# STM32U545 register map
File version: 1.7
CPU: CM33 r0p1, little endian, MPU, FPU, 4 interrupt priority bits
Registers are 32-bit, read-write, reset 0x0 unless marked. A register's access mark holds for its fields unless they carry their own. Offsets are from the block's base; [hi:lo] are bit positions; {n}, {i} and the like mark numbered series; 'fields as' and 'values as' point back to an identical list.

## USB — USB full speed
Base 0x40016000
Same registers: SEC_USB 0x50016000
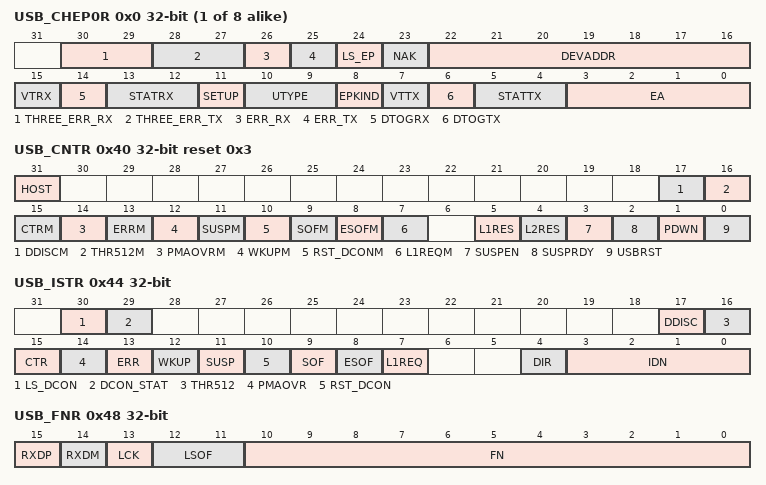
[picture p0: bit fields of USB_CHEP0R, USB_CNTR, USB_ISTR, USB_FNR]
{0x0+4i} USB_CHEP{i}R access per field (i=0..7) — USB endpoint/channel {i} register
  [30:29] THREE_ERR_RX rw — Three errors for an IN transaction
    0=Less than 3 errors received; 1=More than 3 errors received, last error is timeout error; 2=More than 3 errors received, last error is data error (CRC error); 3=More than 3 errors received, last error is protocol error (invalid PID, false EOP, bitstuffing error, SYNC error)
  [28:27] THREE_ERR_TX rw — Three errors for an OUT or SETUP transaction
    values as THREE_ERR_RX
  [26] ERR_RX rw — Received error for an IN transaction
  [25] ERR_TX rw — Received error for an OUT/SETUP transaction
  [24] LS_EP rw — Low speed endpoint host with HUB only
    0=Full speed endpoint; 1=Low speed endpoint
  [23] NAK rw — Host mode
  [22:16] DEVADDR rw — Host mode
  [15] VTRX rw — USB valid transaction received
  [14] DTOGRX wo — Data Toggle, for reception transfers
  [13:12] STATRX wo — Status bits, for reception transfers
  [11] SETUP ro — Setup transaction completed
  [10:9] UTYPE rw — USB type of transaction
  [8] EPKIND rw — endpoint/channel kind
  [7] VTTX rw — Valid USB transaction transmitted
  [6] DTOGTX wo — Data toggle, for transmission transfers
  [5:4] STATTX wo — Status bits, for transmission transfers
  [3:0] EA rw — endpoint/channel address
0x40 USB_CNTR access per field reset 0x3
  [31] HOST rw — HOST mode
    0=USB Device function; 1=USB host function
  [17] DDISCM rw — Device disconnection mask
    0=Device disconnection interrupt disabled; 1=Device disconnection interrupt enabled
  [16] THR512M rw — 512 byte threshold interrupt mask
    0=512 byte threshold interrupt disabled; 1=512 byte threshold interrupt enabled
  [15] CTRM rw — Correct transfer interrupt mask
    0=Correct transfer (CTR) interrupt disabled; 1=CTR interrupt enabled, an interrupt request is generated when the corresponding bit in the USB_ISTR register is set
  [14] PMAOVRM rw — Packet memory area over / underrun interrupt mask
    0=PMAOVR interrupt disabled; 1=PMAOVR interrupt enabled, an interrupt request is generated when the corresponding bit in the USB_ISTR register is set
  [13] ERRM rw — Error interrupt mask
    0=ERR interrupt disabled; 1=ERR interrupt enabled, an interrupt request is generated when the corresponding bit in the USB_ISTR register is set
  [12] WKUPM rw — Wakeup interrupt mask
    0=WKUP interrupt disabled; 1=WKUP interrupt enabled, an interrupt request is generated when the corresponding bit in the USB_ISTR register is set
  [11] SUSPM rw — Suspend mode interrupt mask
    0=Suspend mode request (SUSP) interrupt disabled; 1=SUSP interrupt enabled, an interrupt request is generated when the corresponding bit in the USB_ISTR register is set
  [10] RST_DCONM rw — USB reset request (Device mode) or device connect/disconnect (Host mode) interrupt mask
    0=RESET interrupt disabled; 1=RESET interrupt enabled, an interrupt request is generated when the corresponding bit in the USB_ISTR register is set
  [9] SOFM rw — Start of frame interrupt mask
    0=SOF interrupt disabled; 1=SOF interrupt enabled, an interrupt request is generated when the corresponding bit in the USB_ISTR register is set
  [8] ESOFM rw — Expected start of frame interrupt mask
    0=Expected start of frame (ESOF) interrupt disabled; 1=ESOF interrupt enabled, an interrupt request is generated when the corresponding bit in the USB_ISTR register is set
  [7] L1REQM rw — LPM L1 state request interrupt mask
    0=LPM L1 state request (L1REQ) interrupt disabled; 1=L1REQ interrupt enabled, an interrupt request is generated when the corresponding bit in the USB_ISTR register is set
  [5] L1RES rw — L1 remote wakeup / resume driver
    0=No effect; 1=Send 50 us remote-wakeup signaling to host
  [4] L2RES rw — L2 remote wakeup / resume driver
    0=No effect; 1=Send L2 resume signaling to device
  [3] SUSPEN rw — Suspend state enable
    0=B_0x0_DEVICE_MODE (No effect.); 1=B_0x1_DEVICE_MODE (Enter L1/L2 suspend)
  [2] SUSPRDY ro — Suspend state effective
    0=Normal operation; 1=Suspend state
  [1] PDWN rw — Power down
    0=Exit power down; 1=Enter power down mode
  [0] USBRST rw — USB Reset
    0=B_0x0_DEVICE_MODE (No effect); 1=B_0x1_DEVICE_MODE (USB core is under reset)
0x44 USB_ISTR access per field — USB interrupt status register
  [30] LS_DCON ro — Low speed device connected
  [29] DCON_STAT ro — Device connection status
    0=No device connected; 1=FS or LS device connected to the host
  [17] DDISC rw — Device connection
  [16] THR512 rw — 512 byte threshold interrupt
  [15] CTR ro — Completed transfer in host mode
  [14] PMAOVR rw — Packet memory area over / underrun
  [13] ERR rw — Error
  [12] WKUP rw — Wakeup
  [11] SUSP rw — Suspend mode request
  [10] RST_DCON rw — USB reset request (Device mode) or device connect/disconnect (Host mode)
  [9] SOF rw — Start of frame
  [8] ESOF rw — Expected start of frame
  [7] L1REQ rw — LPM L1 state request
  [4] DIR ro — Direction of transaction
  [3:0] IDN ro — Device Endpoint / host channel identification number
0x48 USB_FNR ro (reset mask 0xFFFFF000) — USB frame number register
  [15] RXDP — Receive data + line status
  [14] RXDM — Receive dataline status
  [13] LCK — Locked
  [12:11] LSOF — Lost SOF
  [10:0] FN — Frame number
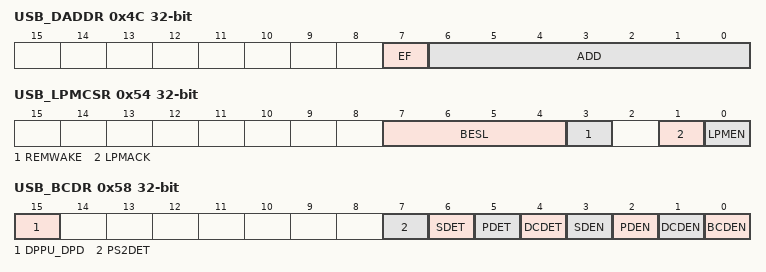
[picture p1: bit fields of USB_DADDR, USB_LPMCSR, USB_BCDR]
0x4C USB_DADDR
  [7] EF — Enable function
  [6:0] ADD — Device address
0x54 USB_LPMCSR access per field
  [7:4] BESL ro — BESL value
  [3] REMWAKE ro — bRemoteWake value
  [1] LPMACK rw — LPM token acknowledge enable
    0=the valid LPM token is NYET; 1=the valid LPM token is ACK
  [0] LPMEN rw — LPM support enable
0x58 USB_BCDR access per field
  [15] DPPU_DPD rw — DP pull-up / DPDM pull-down
  [7] PS2DET ro — DM pull-up detection status
    0=Normal port detected (connected to SDP, ACA, CDP or DCP); 1=PS2 port or proprietary charger detected
  [6] SDET ro — Secondary detection (SD) status
    0=CDP detected; 1=DCP detected
  [5] PDET ro — Primary detection (PD) status
    0=no BCD support detected (connected to SDP or proprietary device); 1=BCD support detected (connected to ACA, CDP or DCP)
  [4] DCDET ro — Data contact detection (DCD) status
    0=data lines contact not detected; 1=data lines contact detected
  [3] SDEN rw — Secondary detection (SD) mode enable
  [2] PDEN rw — Primary detection (PD) mode enable
  [1] DCDEN rw — Data contact detection (DCD) mode enable
  [0] BCDEN rw — Battery charging detector (BCD) enable
